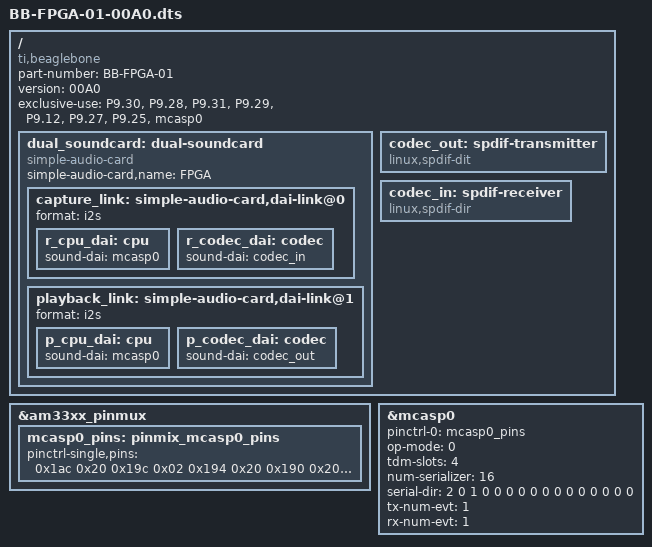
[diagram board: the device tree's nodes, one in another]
/dts-v1/;
/plugin/;

/ {
	compatible = "ti,beaglebone", "ti,beaglebone-black", "ti,beaglebone-green";

	/* part-number */
	part-number = "BB-FPGA-01";

	/* version */
	version = "00A0";
	
	/* state the resources this cape uses */
	exclusive-use =
		/* audio */
		"P9.30",	/* mcasp0_axr0 		audio in */
		"P9.28",	/* mcasp0_axr2 		audio out */
		"P9.31",	/* mcasp0_ahclkx	transmit bitclock */
		"P9.29",	/* mcasp0_fsx 		transmit frameclock */
		"P9.12",	/* mcasp0_aclkr		receive bitclock */
		"P9.27",	/* mcasp0_fsr		receive frameclock */
		"P9.25",	/* mcasp0_ahclkx 	masterclock */
		/* the hardware ip uses */
	"mcasp0";

    fragment@0 {
        target-path = "/";
        __overlay__ {
		
			/*clk_mcasp0_fixed: clk_mcasp0_fixed {
				#clock-cells = <0>;
				compatible = "fixed-clock";
				clock-frequency = <24576000>;
			};

			clk_mcasp0: clk_mcasp0 {
				#clock-cells = <0>;
				compatible = "gpio-gate-clock";
				clocks = <&clk_mcasp0_fixed>;
			};*/
			
            dual_soundcard: dual-soundcard {
                compatible = "simple-audio-card";
                simple-audio-card,name = "FPGA";

                status="okay";

                capture_link: simple-audio-card,dai-link@0 {
                    format = "i2s";

                    r_cpu_dai: cpu {
						sound-dai = <&mcasp0>;
						/* clocks = <&clk_mcasp0>;*/
					};

                    r_codec_dai: codec {
                        sound-dai = <&codec_in>;
                    };
                };

                playback_link: simple-audio-card,dai-link@1 {
                    format = "i2s";

                    p_cpu_dai: cpu {
                        sound-dai = <&mcasp0>;
						/* clocks = <&clk_mcasp0>;*/
                    };

                    p_codec_dai: codec {
                        sound-dai = <&codec_out>;
                    };
                };

            };
        };
        };

    fragment@1 {
        target-path = "/";
        __overlay__ {
            codec_out: spdif-transmitter {
                #address-cells = <0>;
                #size-cells = <0>;
                #sound-dai-cells = <0>;
                compatible = "linux,spdif-dit";
                status = "okay";
            };
            codec_in: spdif-receiver {
                #address-cells = <0>;
                #size-cells = <0>;
                #sound-dai-cells = <0>;
                compatible = "linux,spdif-dir";
                status = "okay";
            };
        };
    };
	
	fragment@3 {
		target = <&am33xx_pinmux>;
		__overlay__ {
			mcasp0_pins: pinmix_mcasp0_pins {
				pinctrl-single,pins = <
					0x1ac 0x20		/* mcasp0_ahclkx,	MODE0 | INPUT_PULLDOWN | P9_25 */
					0x19c 0x02		/* mcasp0_axr2,		MODE2 | OUTPUT_PULLDOWN | P9_28 */
					0x194 0x20		/* mcasp0_fsx, 		MODE0 | INPUT_PULLDOWN | P9_29 */
					0x190 0x20		/* mcasp0_aclkx, 	MODE0 | INPUT_PULLDOWN | P9_31 */
					0x1a4 0x20		/* mcasp0_fsr,		MODE0 | INPUT_PULLDOWN | P9_27 */
					0x078 0x26		/* mcasp0_aclkr,	MODE6 | INPUT_PULLDOWN | P9_12 */
					0x198 0x20		/* mcasp0_axr0, 	MODE0 | INPUT_PULLDOWN | P9_30 */
				>;
			};
		};
	};
	
	fragment@4 {
		target = <&mcasp0>;
		__overlay__ {
			pinctrl-names = "default";
			pinctrl-0 = <&mcasp0_pins>;

			status = "okay";

			op-mode = <0>;	/* MCASP_IIS_MODE */
			tdm-slots = <4>;
			num-serializer = <16>;
			serial-dir = <  /* 0: INACTIVE, 1: TX, 2: RX */
				2 0 1 0
				0 0 0 0
				0 0 0 0
				0 0 0 0
			>;
			tx-num-evt = <1>;
			rx-num-evt = <1>;
		};
	};

};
